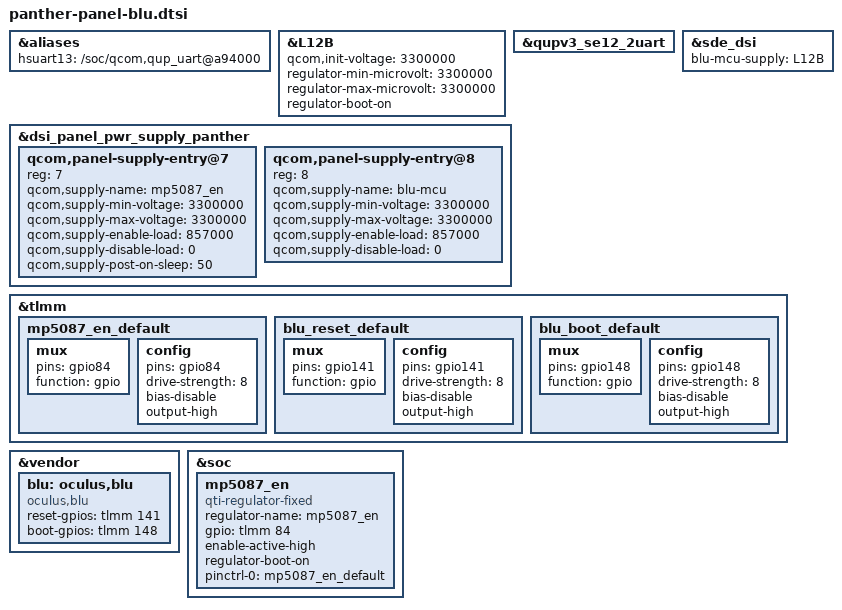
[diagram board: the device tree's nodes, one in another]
// SPDX-License-Identifier: GPL-2.0

&aliases {
	// BLU UART
	hsuart13 = "/soc/qcom,qup_uart@a94000"; /* /dev/ttyHS13 */
};

&L12B {
	qcom,init-voltage = <3300000>;
	regulator-min-microvolt = <3300000>;
	regulator-max-microvolt = <3300000>;
	regulator-boot-on;
};

&qupv3_se12_2uart {
	/* BLU FW flashing */
	status = "ok";
};

&sde_dsi {
	blu-mcu-supply = <&L12B>;
};

&dsi_panel_pwr_supply_panther {
	qcom,panel-supply-entry@7 {
		reg = <7>;
		qcom,supply-name = "mp5087_en";
		qcom,supply-min-voltage = <3300000>;
		qcom,supply-max-voltage = <3300000>;
		qcom,supply-enable-load = <857000>;
		qcom,supply-disable-load = <0>;
		qcom,supply-post-on-sleep = <50>;
	};

	qcom,panel-supply-entry@8 {
		reg = <8>;
		qcom,supply-name = "blu-mcu";
		qcom,supply-min-voltage = <3300000>;
		qcom,supply-max-voltage = <3300000>;
		qcom,supply-enable-load = <857000>;
		qcom,supply-disable-load = <0>;
	};
};

&tlmm {
	mp5087_en_default: mp5087_en_default {
		mux {
			pins = "gpio84";
			function = "gpio";
		};

		config {
			pins = "gpio84";
			drive-strength = <8>;
			bias-disable;
			output-high;
		};
	};

	blu_reset_default: blu_reset_default {
		mux {
			pins = "gpio141";
			function = "gpio";
		};

		config {
			pins = "gpio141";
			drive-strength = <8>;
			bias-disable;
			output-high;
		};
	};

	blu_boot_default: blu_boot_default {
		mux {
			pins = "gpio148";
			function = "gpio";
		};

		config {
			pins = "gpio148";
			drive-strength = <8>;
			bias-disable;
			output-high;
		};
	};
};

&vendor {
	blu: oculus,blu {
		status = "ok";
		compatible = "oculus,blu";
		reset-gpios = <&tlmm 141 0>;
		boot-gpios = <&tlmm 148 0>;
	};
};

&soc {
	mp5087_en: mp5087_en {
		compatible = "qti-regulator-fixed";
		regulator-name = "mp5087_en";
		gpio = <&tlmm 84 0>;
		enable-active-high;
		regulator-boot-on;
		pinctrl-names = "default";
		pinctrl-0 = <&mp5087_en_default>;
	};
};
